# AC78xx register map
Vendor: AutoChips; Series: AC78xx; File version: 1.0
CPU: CM3 r2p1, little endian, MPU, no FPU, 3 interrupt priority bits
Registers are 32-bit, read-write, no defined reset value unless marked. A register's access mark holds for its fields unless they carry their own. Offsets are from the block's base; [hi:lo] are bit positions; lines under a group give offsets from that group; {n}, {i} and the like mark numbered series.

## CTU — Connect Module Unit
Base 0x40016000; register names take the prefix CTU_
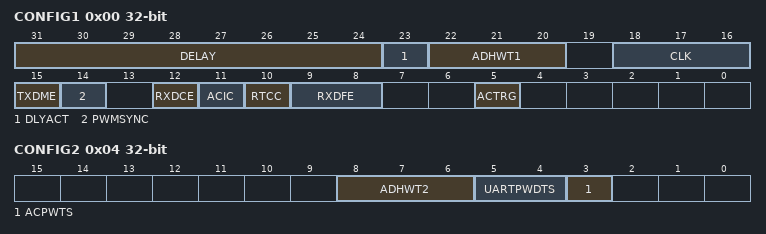
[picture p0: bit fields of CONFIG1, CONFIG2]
0x00 CONFIG1 — CTU Configuration Register 1
  [31:24] DELAY — Trigger Delay Counter
  [23] DLYACT — Trigger Delay Active
    0=Delay is inactive; 1=Delay is active
  [22:20] ADHWT1 — ADC Hardware Trigger Source for regular group
    0=RTC Overflow as ADC hardware Trigger; 1=PWM0 as ADC Hardware Trigger; 2=PWM2 Init Trigger with 8-bit programmable counter delay; 3=PWM2 Match Trigger with 8-bit programmable counter delay; 4=Timer Channel0 overflow as ADC Hardware Trigger; 5=Timer Channel1 overflow as ADC hardware Trigger; 6=ACMP0 Out as ADC Hardware Trigger; 7=ACMP1 Out as ADC Hardware Trigger
  [18:16] CLK — BUS Clock Output Selection
    0=BUS Clock; 1=Bus Divided by 2; 2=Bus Divided by 4; 3=Bus Divided by 8; 4=Bus Divided by 16; 5=Bus Divided by 32; 6=Bus Divided by 64; 7=Bus Divided by 128
  [15] TXDME — UART1 TX Modulation Selection
    0=UART1_TX is connected to PIN out directly; 1=UART1_TX is modulated by PWM0 Channel 0
  [14] PWMSYNC — PWM SW Synchronization Selection
    0=No Synchronization triggered; 1=Generate PWM Synchronization to trigger PWM Modules
  [12] RXDCE — UART0_RX Capture Selection
    0=UART1_RX input connect to UART1 Only; 1=UART1_RX input connected to PWM0 Channel 1
  [11] ACIC — Analog Comparator to Input Capture Enable
    0=ACMP0 Output is not connected to PWM1 Channel0; 1=ACMP1 Output is connected to PWM1 Channel0
  [10] RTCC — Real-Time Counter Capture
    0=RTC Overflow is not connected to PWM1 Channel 1; 1=RTC overflow is connected to PWM1 Channel 1
  [9:8] RXDFE — UART1 RxD filter Selection
    0=RXD1 input signal is connected to UART1 modulate directly; 1=RXD1 input signal is filtered by ACMP0, then injected to UART1; 2=RXD1 input signal is filtered by ACMP1, then injected to UART1; 3=Not Defined
  [5] ACTRG — ACMP Trigger PWM2 Selection
    0=ACMP0 Output Trigger PWM; 1=ACMP1 Output Trigger PWM
0x04 CONFIG2 — CTU Configuration Register 2
  [8:6] ADHWT2 — ADC Hardware Trigger Source for injection group
    0=RTC Overflow as the ADC hardware trigger; 1=PWM0 as the ADC hardware trigger; 2=PWM2 init trigger with 8-bit programmable count delay as ADC hardware trigger; 3=PWM2 match trigger with 8-bit programmable count delay as ADC hardware trigger; 4=Timer Channel0 overflow as the ADC hardware trigger; 5=Timer Channel1 overflow as the ADC hardware trigger; 6=ACMP0 output as the ADC hardware trigger; 7=ACMP1 output as the ADC hardware trigger
  [5:4] UARTPWDTS — PWDT UART RX Select
    0=UART0 RX is connected to PWDT_IN3; 1=UART1 RX is connected to PWDT_IN3; 2=UART2 RX is connected to PWDT_IN3; 3=ACMP_OUT is Connected to PWTIN3
  [3] ACPWTS — PWDT ACMP_OUT Select
    0=ACMP1_OUT is Connected to PWDT_IN3; 1=ACMP0_OUT is Connected to PWDT_IN3

## LIN0 — LIN Interface
Base 0x40007000; register names take the prefix LIN0_
0x00 SYS — LIN System Control Register
  [1:0] LM — LIN Mode Select
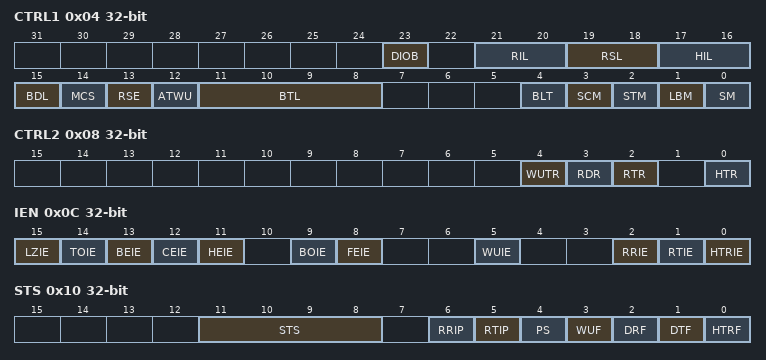
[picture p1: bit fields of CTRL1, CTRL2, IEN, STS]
0x04 CTRL1 — LIN Control Register 1
  [23] DIOB — LIN State machine goes to IDLE on bit error detection
  [21:20] RIL — Response inter byte length between response data
  [19:18] RSL — Response inter space length, only for master mode
  [17:16] HIL — Header inter-byte length between sync field and PID filed in master mode
  [15] BDL — Break delimiter length
  [14] MCS — Disable the hardware checksum calculation
  [13] RSE — LIN Slave Automatic Resynchronization Enable
  [12] ATWU — Control the behavior of the LIN hardware during sleep mode
  [11:8] BTL — LIN Break field transmit length in master mode
  [4] BLT — LIN Break Length threshold select
  [3] SCM — LIN software control Mode enable bit
  [2] STM — LIN Self Test Mode enable bit
  [1] LBM — LIN Loop back Mode enable bit
  [0] SM — LIN Slave Mode enable bit
0x08 CTRL2 — LIN Control register 2
  [4] WUTR — Wakeup TX Request
  [3] RDR — Response Discard Request
  [2] RTR — Data Transmission Request
  [0] HTR — Header Transmission Requeset
0x0C IEN — LIN Interrupt Enable Register
  [15] LZIE — Long Zero Interrupt Enable
  [14] TOIE — Timeout Interrupt Enable
  [13] BEIE — Bit Error Interrupt Enable
  [12] CEIE — Checksum error Interrupt enable
  [11] HEIE — Header Error Interrupt Enable
  [9] BOIE — Buffer Overrun Interrupt enable
  [8] FEIE — Framing Error Interrupt Enable
  [5] WUIE — Wakeup Interrupt enable
  [2] RRIE — Response Reception Complete Interrupt Enable
  [1] RTIE — Response Transmitted Interrupt Enable
  [0] HTRIE — Header Received Interrupt enable
0x10 STS — LIN Status Register
  [11:8] STS ro — LIN mode status
  [6] RRIP ro — Response RX in Progress
  [5] RTIP ro — Response TX in Progress
  [4] PS ro — LIN receive pin state
  [3] WUF write-clear — Wake-up Flag
  [2] DRF write-clear — Data Reception Completed Flag
  [1] DTF write-clear — Data Transmission Completed Flag
  [0] HTRF write-clear — Header Transmission/Reception Flag
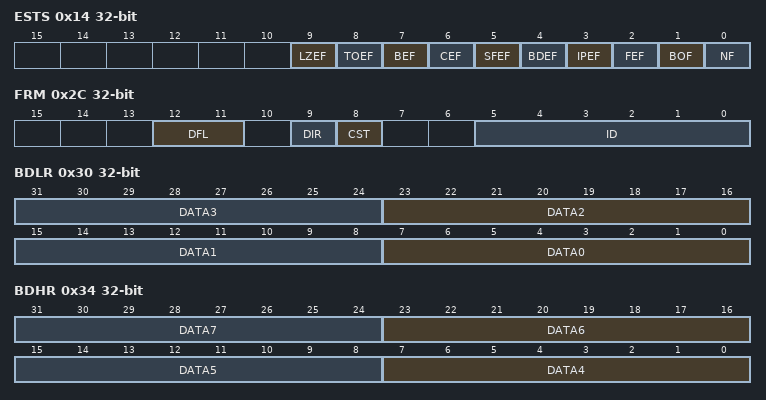
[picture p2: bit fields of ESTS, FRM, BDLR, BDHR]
0x14 ESTS write-clear — LIN Error Status register
  [9] LZEF — Long Zero Error Flag
  [8] TOEF — Time Out Error Flag
  [7] BEF — Bit Error Flag
  [6] CEF — Checksum Error Flag
  [5] SFEF — Synch Field Error Flag
  [4] BDEF — Break Delimiter Error Flag
  [3] IPEF — Identifier Parity Error Flag
  [2] FEF — Framing Error Flag
  [1] BOF — Buffer Overrun Flag
  [0] NF — Noise Flag
0x18 TO1 — LIN Time out control register 1
  [5:0] HTO — Header timeout value
0x1C TO2 — LIN Time out control register 2
  [0] TOEN — Header timeout enable
0x20 IBR — LIN integer baud rate register
  [11:0] IBR — Integer baud rate divide value
0x24 FBR — LIN fractional baud rate register
  [3:0] FBR — Fractional baud rate divide value
0x28 CS — LIN Checksum field register
  [7:0] CS — LIN Checksum field value
0x2C FRM — LIN Frame Control register
  [12:11] DFL — Data field length
  [9] DIR — Direction
  [8] CST — Checksum type
  [5:0] ID — Identifier
0x30 BDLR — Buffer data low register
  [8n+7:8n] DATA{n} (n=0..3)
0x34 BDHR — Buffer data High register
  [8n-25:8n-32] DATA{n} (n=4..7)
0x38 IFEN — LIN ID Filter enable register
  [15:0] EN — Filter Number Enable
0x3C IFMR — LIN ID Filter mode register
  [7:0] IFM — ID Filter Mode
0x40 IFMI — LIN ID Filter match index register
  [4:0] IFMI — ID Filter match index
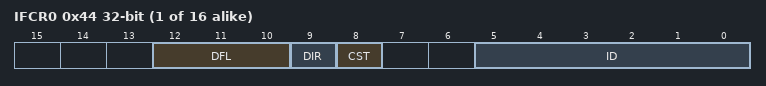
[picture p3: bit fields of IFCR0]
{0x44+4i} IFCR{i} (i=0..15) — LIN ID filter control register
  [12:10] DFL — Data Field Length
  [9] DIR — Direction
  [8] CST — Checksum type
  [5:0] ID — Identifier
